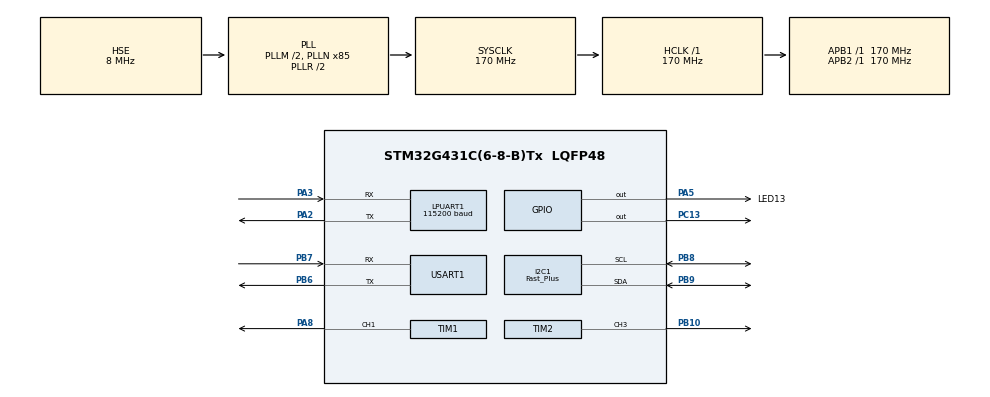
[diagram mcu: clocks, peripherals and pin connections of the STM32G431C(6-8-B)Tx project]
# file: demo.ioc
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I2C1.I2C_Speed_Mode=I2C_Fast_Plus
I2C1.Timing=0x4052060F
LPUART1.BaudRate=115200
Mcu.Family=STM32G4
Mcu.Name=STM32G431C(6-8-B)Tx
Mcu.Package=LQFP48
NVIC.LPUART1_IRQn=true\:0\:0\:false\:false\:true\:true\:true\:true
NVIC.PriorityGroup=NVIC_PRIORITYGROUP_4
NVIC.TIM1_BRK_TIM15_IRQn=true\:15\:0\:false\:false\:true\:false\:true\:true
NVIC.TimeBase=TIM1_BRK_TIM15_IRQn
NVIC.TimeBaseIP=TIM15
PA13.Mode=Serial_Wire
PA13.Signal=SYS_JTMS-SWDIO
PA14.Mode=Serial_Wire
PA14.Signal=SYS_JTCK-SWCLK
PA2.Mode=Asynchronous
PA2.Signal=LPUART1_TX
PA3.Mode=Asynchronous
PA3.Signal=LPUART1_RX
PA5.GPIO_Label=LED13
PA5.Signal=GPIO_Output
PA8.Signal=S_TIM1_CH1
PB10.Signal=S_TIM2_CH3
PB6.Mode=Asynchronous
PB6.Signal=USART1_TX
PB7.Mode=Asynchronous
PB7.Signal=USART1_RX
PB8-BOOT0.GPIO_Pu=GPIO_PULLUP
PB8-BOOT0.Mode=I2C
PB8-BOOT0.Signal=I2C1_SCL
PB9.GPIO_Pu=GPIO_PULLUP
PB9.Mode=I2C
PB9.Signal=I2C1_SDA
PC13.Signal=GPIO_Output
PC14-OSC32_IN.Mode=LSE-External-Oscillator
PC14-OSC32_IN.Signal=RCC_OSC32_IN
PC15-OSC32_OUT.Mode=LSE-External-Oscillator
PC15-OSC32_OUT.Signal=RCC_OSC32_OUT
PF0-OSC_IN.Mode=HSE-External-Clock-Source
PF0-OSC_IN.Signal=RCC_OSC_IN
ProjectManager.HeapSize=0x200
ProjectManager.StackSize=0x400
ProjectManager.TargetToolchain=MDK-ARM V5.32
RCC.ADC12Freq_Value=170000000
RCC.AHBFreq_Value=170000000
RCC.APB1Freq_Value=170000000
RCC.APB1TimFreq_Value=170000000
RCC.APB2Freq_Value=170000000
RCC.APB2TimFreq_Value=170000000
RCC.CortexFreq_Value=170000000
RCC.EXTERNAL_CLOCK_VALUE=12288000
RCC.FDCANCLockSelection=RCC_FDCANCLKSOURCE_HSE
RCC.HCLKFreq_Value=170000000
RCC.HSE_VALUE=8000000
RCC.HSI48_VALUE=48000000
RCC.HSI_VALUE=16000000
RCC.PLLM=RCC_PLLM_DIV2
RCC.PLLN=85
RCC.PLLQ=RCC_PLLQ_DIV4
RCC.PLLSourceVirtual=RCC_PLLSOURCE_HSE
RCC.SYSCLKFreq_VALUE=170000000
RCC.SYSCLKSource=RCC_SYSCLKSOURCE_PLLCLK
RCC.USBFreq_Value=85000000
RCC.VCOOutputFreq_Value=340000000
SH.S_TIM1_CH1.0=TIM1_CH1,Output Compare1 CH1
SH.S_TIM2_CH3.0=TIM2_CH3,PWM Generation3 CH3
TIM1.Channel-Output\ Compare1\ CH1=TIM_CHANNEL_1
TIM2.Channel-PWM\ Generation3\ CH3=TIM_CHANNEL_3
TIM2.PeriodNoDither=5000-1
TIM2.Prescaler=17-1
USART1.VirtualMode-Asynchronous=VM_ASYNC
VP_SYS_VS_DBSignals.Mode=DisableDeadBatterySignals
VP_SYS_VS_tim15.Mode=TIM15
board=custom

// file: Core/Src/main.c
/* USER CODE BEGIN Header */
/**
  ******************************************************************************
  * @file           : main.c
  * @brief          : Main program body
  ******************************************************************************
  * @attention
  *
  * Copyright (c) 2026 STMicroelectronics.
  * All rights reserved.
  *
  * This software is licensed under terms that can be found in the LICENSE file
  * in the root directory of this software component.
  * If no LICENSE file comes with this software, it is provided AS-IS.
  *
  ******************************************************************************
  */
/* USER CODE END Header */
#include "main.h"
#include "i2c.h"
#include "usart.h"
#include "tim.h"
#include "gpio.h"

void SystemClock_Config(void);

int main(void)
{

  /* USER CODE BEGIN 1 */
uint8_t byteNumber = 1;
  /* USER CODE END 1 */

  /* MCU Configuration--------------------------------------------------------*/

  /* Reset of all peripherals, Initializes the Flash interface and the Systick. */
  HAL_Init();

  /* Configure the system clock */
  SystemClock_Config();

  /* Initialize all configured peripherals */
  MX_GPIO_Init();
  MX_USART1_UART_Init();
  MX_LPUART1_UART_Init();
  MX_I2C1_Init();
  MX_TIM2_Init();
  MX_TIM1_Init();

  /* Infinite loop */
  while (1)
  {
		HAL_UART_Transmit(&hlpuart1, &byteNumber, 1, 100);
		HAL_Delay(1000);
  }
}

void SystemClock_Config(void)
{
  RCC_OscInitTypeDef RCC_OscInitStruct = {0};
  RCC_ClkInitTypeDef RCC_ClkInitStruct = {0};

  /** Configure the main internal regulator output voltage
  */
  HAL_PWREx_ControlVoltageScaling(PWR_REGULATOR_VOLTAGE_SCALE1_BOOST);

  /** Initializes the RCC Oscillators according to the specified parameters
  * in the RCC_OscInitTypeDef structure.
  */
  RCC_OscInitStruct.OscillatorType = RCC_OSCILLATORTYPE_HSE;
  RCC_OscInitStruct.HSEState = RCC_HSE_BYPASS;
  RCC_OscInitStruct.PLL.PLLState = RCC_PLL_ON;
  RCC_OscInitStruct.PLL.PLLSource = RCC_PLLSOURCE_HSE;
  RCC_OscInitStruct.PLL.PLLM = RCC_PLLM_DIV2;
  RCC_OscInitStruct.PLL.PLLN = 85;
  RCC_OscInitStruct.PLL.PLLP = RCC_PLLP_DIV2;
  RCC_OscInitStruct.PLL.PLLQ = RCC_PLLQ_DIV4;
  RCC_OscInitStruct.PLL.PLLR = RCC_PLLR_DIV2;
  if (HAL_RCC_OscConfig(&RCC_OscInitStruct) != HAL_OK)
  {
    Error_Handler();
  }

  /** Initializes the CPU, AHB and APB buses clocks
  */
  RCC_ClkInitStruct.ClockType = RCC_CLOCKTYPE_HCLK|RCC_CLOCKTYPE_SYSCLK
                              |RCC_CLOCKTYPE_PCLK1|RCC_CLOCKTYPE_PCLK2;
  RCC_ClkInitStruct.SYSCLKSource = RCC_SYSCLKSOURCE_PLLCLK;
  RCC_ClkInitStruct.AHBCLKDivider = RCC_SYSCLK_DIV1;
  RCC_ClkInitStruct.APB1CLKDivider = RCC_HCLK_DIV1;
  RCC_ClkInitStruct.APB2CLKDivider = RCC_HCLK_DIV1;

  if (HAL_RCC_ClockConfig(&RCC_ClkInitStruct, FLASH_LATENCY_4) != HAL_OK)
  {
    Error_Handler();
  }
}

void HAL_TIM_PeriodElapsedCallback(TIM_HandleTypeDef *htim)
{
  if (htim->Instance == TIM15)
  {
    HAL_IncTick();
  }
}

void Error_Handler(void)
{
  __disable_irq();
  while (1)
  {
  }
}
